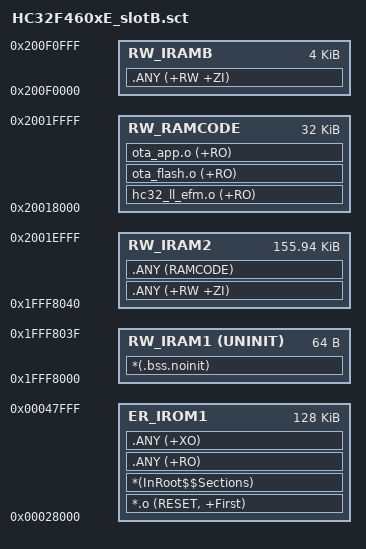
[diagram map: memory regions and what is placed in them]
; ****************************************************************
; HC32F460 报警板 App —— 槽 B 分散加载 分散加载（链接基址 0x00028000）
; 布局见 docs/ota_boot_design.md v0.2 §3
;
; 关键：RW_RAMCODE 段放【片内 Flash 擦/写期间必须执行的代码】—— 此时取指不能来自 Flash！
;   这不是优化，是【正确性要求】：
;    App 启动早期 ota_app_boot_confirm() 会擦写标志扇区(0x7E000)，
;    若这条路径上的代码(含调用者)在 Flash 里执行，CPU 会在擦写期间取指失败而卡死。
;   教训：只把 __RAM_FUNC 标的函数放进 .ANY (RAMCODE) 不够 —— 调用者也要进 RAM。
; ****************************************************************
LR_IROM1 0x00028000 0x00020000  {    ; 槽 B 分散加载
    ER_IROM1 0x00028000 0x00020000  {
        *.o (RESET, +First)
        *(InRoot$$Sections)
        .ANY (+RO)
        .ANY (+XO)
    }
    RW_IRAM1 0x1FFF8000 UNINIT 0x00000040  {
        *(.bss.noinit)
    }
    RW_IRAM2 0x1FFF8040 0x00026FC0  {
        .ANY (+RW +ZI)
        .ANY (RAMCODE)
    }
    RW_IRAMB 0x200F0000 0x00001000  {
        .ANY (+RW +ZI)
    }
    RW_RAMCODE 0x20018000 0x00008000  {  ; 片内 Flash 擦/写执行区（必须 RAM）
        hc32_ll_efm.o (+RO)
        ota_flash.o (+RO)
        ota_app.o (+RO)
    }
}
